# STM32MP153 register map
File version: 1.3
CPU: CM4 r0p1, little endian, no MPU, FPU, 4 interrupt priority bits
Registers are 32-bit, read-write, reset 0x0 unless marked. A register's access mark holds for its fields unless they carry their own. Offsets are from the block's base; [hi:lo] are bit positions; {n}, {i} and the like mark numbered series.

## CRYP1
Base 0x54001000
Same registers: CRYP2 0x4C005000
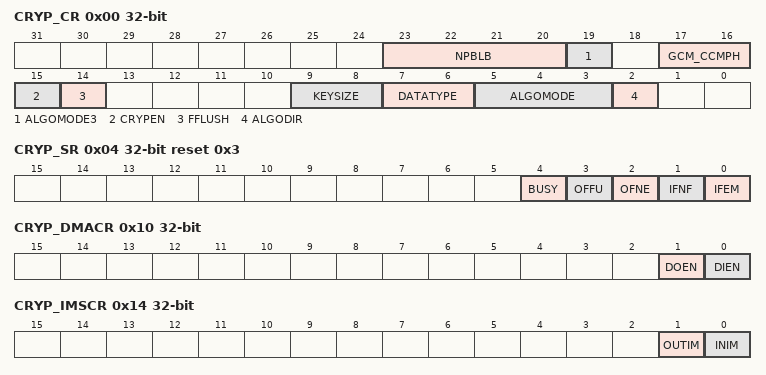
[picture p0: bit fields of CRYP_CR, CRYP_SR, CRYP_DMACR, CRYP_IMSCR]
0x00 CRYP_CR access per field — CRYP control register
  [23:20] NPBLB rw, [19] ALGOMODE3 rw, [17:16] GCM_CCMPH rw, [15] CRYPEN rw, [14] FFLUSH wo, [9:8] KEYSIZE rw, [7:6] DATATYPE rw, [5:3] ALGOMODE rw, [2] ALGODIR rw
0x04 CRYP_SR ro reset 0x3 — CRYP status register
  [4] BUSY, [3] OFFU, [2] OFNE, [1] IFNF, [0] IFEM
0x08 CRYP_DIN — The CRYP_DIN register is the data input register. It is 32-bit wide. It is used to enter into the input FIFO up to four 64-bit blocks (TDES) or two 128-bit blocks (AES) of plaintext (when encrypting) or ciphertext (when decrypting), one 32-bit word at a time. To fit different data sizes, the data can be swapped after processing by configuring the DATATYPE bits in the CRYP_CR register. Refer to Section39.3.16: CRYP data registers and data swapping for more details. When CRYP_DIN register is written to the data are pushed into the input FIFO. If CRYPEN = 1, when at least two 32-bit words in the DES/TDES mode have been pushed into the input FIFO (four words in the AES mode), and when at least two words are free in the output FIFO (four words in the AES mode), the CRYP engine starts an encrypting or decrypting process. When CRYP_DIN register is read: If CRYPEN = 0, the FIFO is popped, and then the data present in the Input FIFO are returned, from the oldest one (first reading) to the newest one (last reading). The IFEM flag must be checked before each read operation to make sure that the FIFO is not empty. if CRYPEN = 1, an undefined value is returned. After the CRYP_DIN register has been read once or several times, the FIFO must be flushed by setting the FFLUSH bit prior to processing new data.
  [31:0] DATAIN
0x0C CRYP_DOUT ro — The CRYP_DOUT register is the data output register. It is read-only and 32-bit wide. It is used to retrieve from the output FIFO up to four 64-bit blocks (TDES) or two 128-bit blocks (AES) of plaintext (when encrypting) or ciphertext (when decrypting), one 32-bit word at a time. To fit different data sizes, the data can be swapped after processing by configuring the DATATYPE bits in the CRYP_CR register. Refer to Section39.3.16: CRYP data registers and data swapping for more details. When CRYP_DOUT register is read, the last data entered into the output FIFO (pointed to by the read pointer) is returned.
  [31:0] DATAOUT
0x10 CRYP_DMACR — CRYP DMA control register
  [1] DOEN, [0] DIEN
0x14 CRYP_IMSCR — The CRYP_IMSCR register is the interrupt mask set or clear register. It is a read/write register. When a read operation is performed, this register gives the current value of the mask applied to the relevant interrupt. Writing 1 to the particular bit sets the mask, thus enabling the interrupt to be read. Writing 0 to this bit clears the corresponding mask. All the bits are cleared to 0 when the peripheral is reset.
  [1] OUTIM, [0] INIM
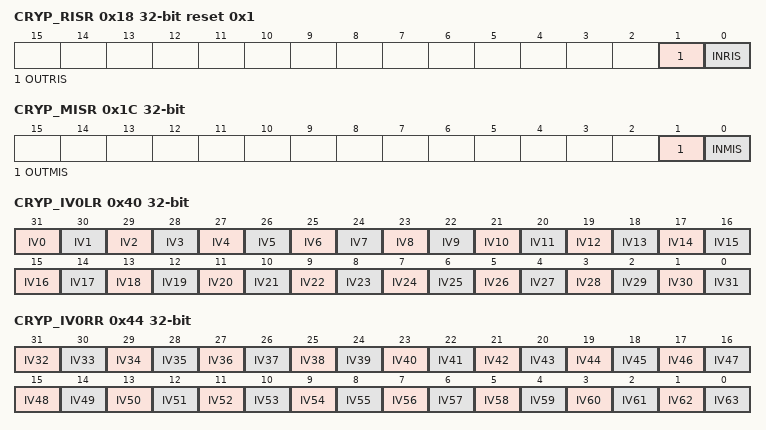
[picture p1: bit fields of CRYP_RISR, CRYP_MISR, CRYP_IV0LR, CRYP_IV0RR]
0x18 CRYP_RISR ro reset 0x1 — The CRYP_RISR register is the raw interrupt status register. It is a read-only register. When a read operation is performed, this register gives the current raw status of the corresponding interrupt, i.e. the interrupt information without taking CRYP_IMSCR mask into account. Write operations have no effect.
  [1] OUTRIS, [0] INRIS
0x1C CRYP_MISR ro — The CRYP_MISR register is the masked interrupt status register. It is a read-only register. When a read operation is performed, this register gives the current masked status of the corresponding interrupt, i.e. the interrupt information taking CRYP_IMSCR mask into account. Write operations have no effect.
  [1] OUTMIS, [0] INMIS
0x20 CRYP_K0LR wo — CRYP key registers contain the cryptographic keys. In DES/TDES mode, the keys are 64-bit binary values (number from left to right, that is the leftmost bit is bit 1) and named K1, K2 and K3 (K0 is not used). Each key consists of 56 information bits and 8 parity bits. In AES mode, the key is considered as a single 128, 192 or 256 bits long sequence K0K1K2...K127/191/255. The AES key is entered into the registers as follows: for AES-128: K0..K127 corresponds to b127..b0 (b255..b128 are not used), for AES-192: K0..K191 corresponds to b191..b0 (b255..b192 are not used), for AES-256: K0..K255 corresponds to b255..b0. In all cases key bit K0 is the leftmost bit in CRYP inner memory and register bit b0 is the rightmost bit in corresponding CRYP_KxLR key register. For more information refer to Section39.3.17: CRYP key registers. Write accesses to these registers are disregarded when the cryptographic processor is busy (bit BUSY = 1 in the CRYP_SR register)
  [31:0] K
{0x24+8i} CRYP_K{i}RR wo (i=0..3) — Refer to Section39.6.9: CRYP key register 0L (CRYP_K0LR) for details.
  [31:0] K
{0x20+8i} CRYP_K{i}LR wo (i=1..3) — Refer to Section39.6.9: CRYP key register 0L (CRYP_K0LR) for details.
  [31:0] K
0x40 CRYP_IV0LR — The CRYP_IV0...1(L/R)R are the left-word and right-word registers for the initialization vector (64 bits for DES/TDES and 128 bits for AES). For more information refer to Section39.3.18: CRYP initialization vector registers. IV0 is the leftmost bit whereas IV63 (DES, TDES) or IV127 (AES) are the rightmost bits of the initialization vector. IV1(L/R)R is used only in the AES. Only CRYP_IV0(L/R) is used in DES/TDES. Write access to these registers are disregarded when the cryptographic processor is busy (bit BUSY = 1 in the CRYP_SR register).
  [31-n] IV{n} (n=0..31)
0x44 CRYP_IV0RR — Refer to Section39.6.17: CRYP initialization vector register 0L (CRYP_IV0LR) for details.
  [63-n] IV{n} (n=32..63)
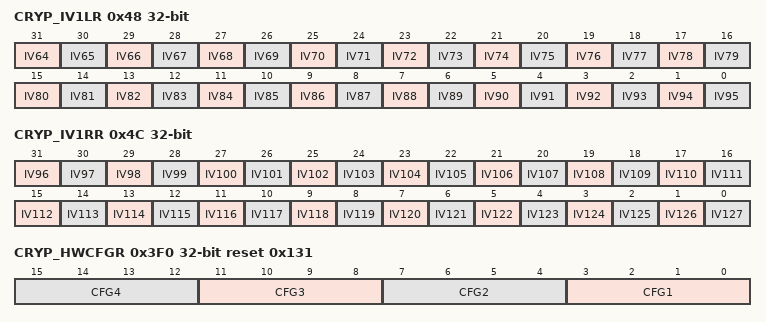
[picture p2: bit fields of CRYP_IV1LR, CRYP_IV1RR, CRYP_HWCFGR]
0x48 CRYP_IV1LR — Refer to Section39.6.17: CRYP initialization vector register 0L (CRYP_IV0LR) for details.
  [95-n] IV{n} (n=64..95)
0x4C CRYP_IV1RR — Refer to Section39.6.17: CRYP initialization vector register 0L (CRYP_IV0LR) for details.
  [127-n] IV{n} (n=96..127)
{0x50+4i} CRYP_CSGCMCCM{i}R (i=0..7) — These registers contain the complete internal register states of the CRYP processor when the GCM/GMAC or CCM algorithm is selected. They are useful when a context swap has to be performed because a high-priority task needs the cryptographic processor while it is already in use by another task. When such an event occurs, the CRYP_CSGCMCCM0..7R and CRYP_CSGCM0..7R (in GCM/GMAC mode) or CRYP_CSGCMCCM0..7R (in CCM mode) registers have to be read and the values retrieved have to be saved in the system memory space. The cryptographic processor can then be used by the preemptive task. Then when the cryptographic computation is complete, the saved context can be read from memory and written back into the corresponding context swap registers.
  [31:0] CSGCMCCM{i}
{0x70+4i} CRYP_CSGCM{i}R (i=0..7) — Please refer to Section39.6.21: CRYP context swap GCM-CCM registers (CRYP_CSGCMCCMxR) for details.
  [31:0] CSGCM{i}
0x3F0 CRYP_HWCFGR ro reset 0x131 — CRYP hardware configuration register
  [4n-1:4n-4] CFG{n} (n=1..4)
0x3F4 CRYP_VERR ro reset 0x22 — CRYP HW Version Register
  [7:0] VER
0x3F8 CRYP_IPIDR ro reset 0x170011 — CRYP Identification
  [31:0] ID
0x3FC CRYP_MID ro reset 0xA3C5DD01 — CRYP HW Magic ID
